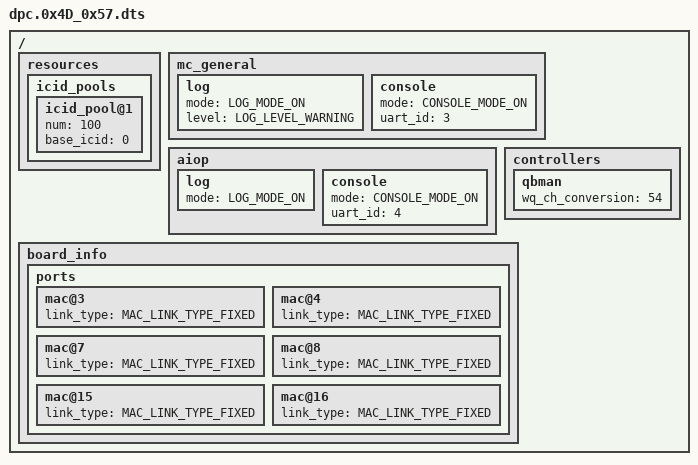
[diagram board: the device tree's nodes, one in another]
/dts-v1/;
/* DPC */
/ {
	resources {
		icid_pools {
			icid_pool@1 {
				num = <100>;
				base_icid = <0>;
			};
		};
	};
	mc_general {
		log {
			mode = "LOG_MODE_ON";
			level = "LOG_LEVEL_WARNING";
		};
		console {
			mode = "CONSOLE_MODE_ON";
			uart_id = <3>;
		};
	};
	aiop {
		log {
			mode = "LOG_MODE_ON";
		};
		console {
			mode = "CONSOLE_MODE_ON";
			uart_id = <4>;
		};
	};
	controllers {
		qbman {
			/* Transform this number of 8-WQ channels into four times
			 * as many 2-WQ channels. This allows the creation of a
			 * larger number of DPCONs.
			 */
			wq_ch_conversion = <54>;
		};
	};
	board_info {
		ports {
			/* For QDS SerDes 0x4d_57: 4 SGMII ports. */
			mac@3 {
				link_type = "MAC_LINK_TYPE_FIXED";
			};
			mac@4 {
				link_type = "MAC_LINK_TYPE_FIXED";
			};
			mac@7 {
				link_type = "MAC_LINK_TYPE_FIXED";
			};
			mac@8 {
				link_type = "MAC_LINK_TYPE_FIXED";
			};
			mac@15 {
				link_type = "MAC_LINK_TYPE_FIXED";
			};
			mac@16 {
				link_type = "MAC_LINK_TYPE_FIXED";
			};
		};
	};
};
